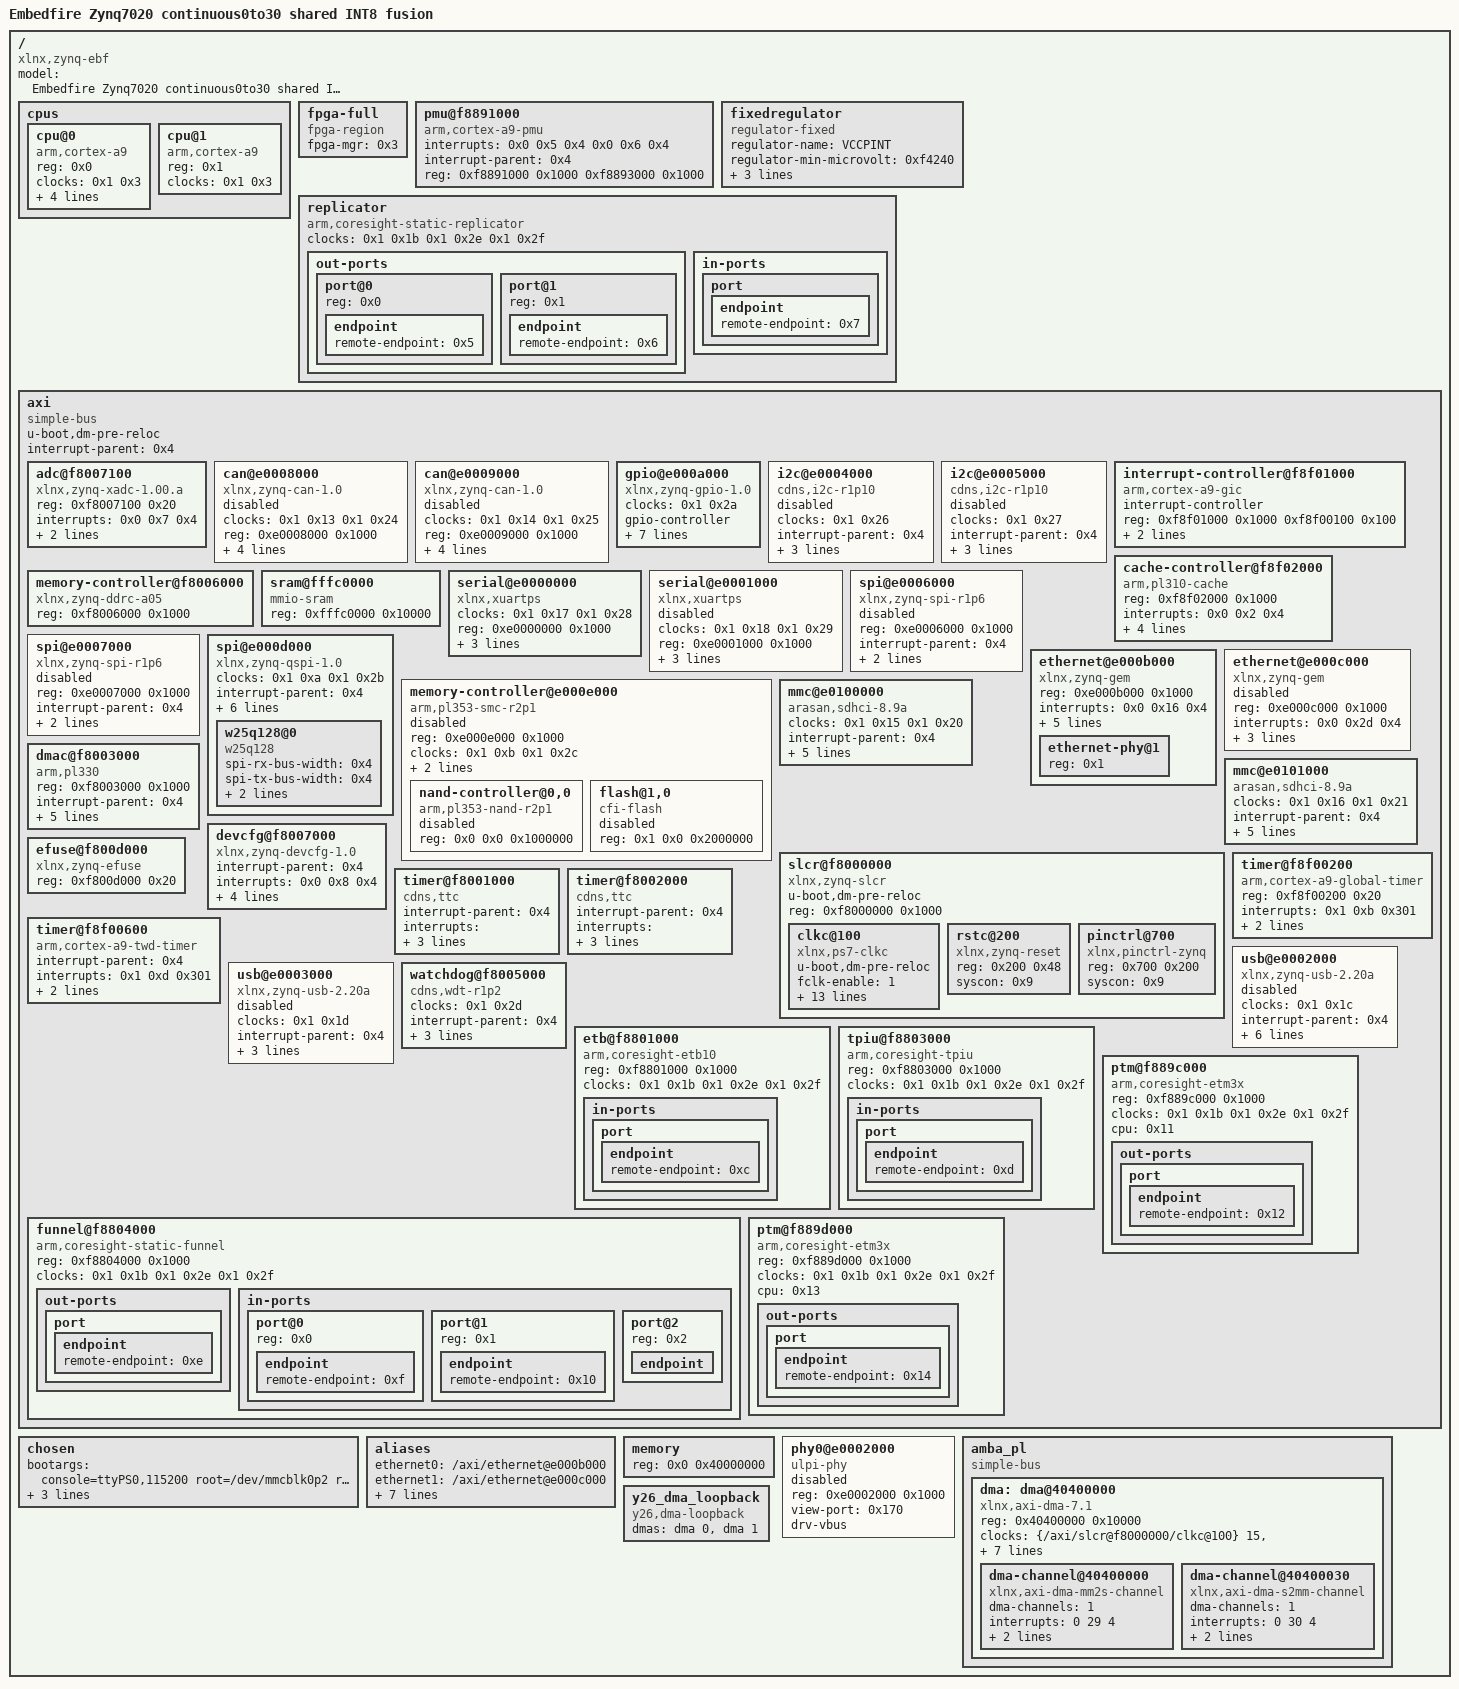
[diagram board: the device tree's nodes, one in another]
/*
 * Minimal PL experiment using the existing board FSBL, kernel and SD rootfs.
 * factory-base.dtsi is decoded from the original /boot/dtb/zynq7020.dtb;
 * its source SHA256 and the actual BOOT.BIN evidence are in verification.json.
 * This is a COMPLETE boot DT, not an overlay to apply to a running old design.
 */
/dts-v1/;

/ {
	#address-cells = <0x1>;
	#size-cells = <0x1>;
	compatible = "xlnx,zynq-ebf", "xlnx,zynq-7000";
	model = "Embedfire ZYNQ Board";

	cpus {
		#address-cells = <0x1>;
		#size-cells = <0x0>;

		cpu@0 {
			compatible = "arm,cortex-a9";
			device_type = "cpu";
			reg = <0x0>;
			clocks = <0x1 0x3>;
			clock-latency = <0x3e8>;
			cpu0-supply = <0x2>;
			operating-points = <0xa2c2b 0xf4240 0x51616 0xf4240>;
			phandle = <0x11>;
		};

		cpu@1 {
			compatible = "arm,cortex-a9";
			device_type = "cpu";
			reg = <0x1>;
			clocks = <0x1 0x3>;
			phandle = <0x13>;
		};
	};

	fpga-full {
		compatible = "fpga-region";
		fpga-mgr = <0x3>;
		#address-cells = <0x1>;
		#size-cells = <0x1>;
		ranges;
		phandle = <0x1a>;
	};

	pmu@f8891000 {
		compatible = "arm,cortex-a9-pmu";
		interrupts = <0x0 0x5 0x4 0x0 0x6 0x4>;
		interrupt-parent = <0x4>;
		reg = <0xf8891000 0x1000 0xf8893000 0x1000>;
	};

	fixedregulator {
		compatible = "regulator-fixed";
		regulator-name = "VCCPINT";
		regulator-min-microvolt = <0xf4240>;
		regulator-max-microvolt = <0xf4240>;
		regulator-boot-on;
		regulator-always-on;
		phandle = <0x2>;
	};

	replicator {
		compatible = "arm,coresight-static-replicator";
		clocks = <0x1 0x1b 0x1 0x2e 0x1 0x2f>;
		clock-names = "apb_pclk", "dbg_trc", "dbg_apb";

		out-ports {
			#address-cells = <0x1>;
			#size-cells = <0x0>;

			port@0 {
				reg = <0x0>;

				endpoint {
					remote-endpoint = <0x5>;
					phandle = <0xd>;
				};
			};

			port@1 {
				reg = <0x1>;

				endpoint {
					remote-endpoint = <0x6>;
					phandle = <0xc>;
				};
			};
		};

		in-ports {

			port {

				endpoint {
					remote-endpoint = <0x7>;
					phandle = <0xe>;
				};
			};
		};
	};

	axi {
		u-boot,dm-pre-reloc;
		compatible = "simple-bus";
		#address-cells = <0x1>;
		#size-cells = <0x1>;
		interrupt-parent = <0x4>;
		ranges;
		phandle = <0x1b>;

		adc@f8007100 {
			compatible = "xlnx,zynq-xadc-1.00.a";
			reg = <0xf8007100 0x20>;
			interrupts = <0x0 0x7 0x4>;
			interrupt-parent = <0x4>;
			clocks = <0x1 0xc>;
			phandle = <0x1c>;
		};

		can@e0008000 {
			compatible = "xlnx,zynq-can-1.0";
			status = "okay";
			clocks = <0x1 0x13 0x1 0x24>;
			clock-names = "can_clk", "pclk";
			reg = <0xe0008000 0x1000>;
			interrupts = <0x0 0x1c 0x4>;
			interrupt-parent = <0x4>;
			tx-fifo-depth = <0x40>;
			rx-fifo-depth = <0x40>;
			phandle = <0x1d>;
		};

		can@e0009000 {
			compatible = "xlnx,zynq-can-1.0";
			status = "disabled";
			clocks = <0x1 0x14 0x1 0x25>;
			clock-names = "can_clk", "pclk";
			reg = <0xe0009000 0x1000>;
			interrupts = <0x0 0x33 0x4>;
			interrupt-parent = <0x4>;
			tx-fifo-depth = <0x40>;
			rx-fifo-depth = <0x40>;
			phandle = <0x1e>;
		};

		gpio@e000a000 {
			compatible = "xlnx,zynq-gpio-1.0";
			#gpio-cells = <0x2>;
			clocks = <0x1 0x2a>;
			gpio-controller;
			interrupt-controller;
			#interrupt-cells = <0x2>;
			interrupt-parent = <0x4>;
			interrupts = <0x0 0x14 0x4>;
			reg = <0xe000a000 0x1000>;
			emio-gpio-width = <0x10>;
			gpio-mask-high = <0x0>;
			gpio-mask-low = <0x5600>;
			phandle = <0xa>;
		};

		i2c@e0004000 {
			compatible = "cdns,i2c-r1p10";
			status = "okay";
			clocks = <0x1 0x26>;
			interrupt-parent = <0x4>;
			interrupts = <0x0 0x19 0x4>;
			reg = <0xe0004000 0x1000>;
			#address-cells = <0x1>;
			#size-cells = <0x0>;
			clock-frequency = <0x61a80>;
			phandle = <0x1f>;
		};

		i2c@e0005000 {
			compatible = "cdns,i2c-r1p10";
			status = "okay";
			clocks = <0x1 0x27>;
			interrupt-parent = <0x4>;
			interrupts = <0x0 0x30 0x4>;
			reg = <0xe0005000 0x1000>;
			#address-cells = <0x1>;
			#size-cells = <0x0>;
			clock-frequency = <0x61a80>;
			phandle = <0x20>;
		};

		interrupt-controller@f8f01000 {
			compatible = "arm,cortex-a9-gic";
			#interrupt-cells = <0x3>;
			interrupt-controller;
			reg = <0xf8f01000 0x1000 0xf8f00100 0x100>;
			num_cpus = <0x2>;
			num_interrupts = <0x60>;
			phandle = <0x4>;
		};

		cache-controller@f8f02000 {
			compatible = "arm,pl310-cache";
			reg = <0xf8f02000 0x1000>;
			interrupts = <0x0 0x2 0x4>;
			arm,data-latency = <0x3 0x2 0x2>;
			arm,tag-latency = <0x2 0x2 0x2>;
			cache-unified;
			cache-level = <0x2>;
			phandle = <0x21>;
		};

		memory-controller@f8006000 {
			compatible = "xlnx,zynq-ddrc-a05";
			reg = <0xf8006000 0x1000>;
			phandle = <0x22>;
		};

		sram@fffc0000 {
			compatible = "mmio-sram";
			reg = <0xfffc0000 0x10000>;
			phandle = <0x23>;
		};

		serial@e0000000 {
			compatible = "xlnx,xuartps", "cdns,uart-r1p8";
			status = "okay";
			clocks = <0x1 0x17 0x1 0x28>;
			clock-names = "uart_clk", "pclk";
			reg = <0xe0000000 0x1000>;
			interrupts = <0x0 0x1b 0x4>;
			cts-override;
			device_type = "serial";
			port-number = <0x0>;
			phandle = <0x24>;
		};

		serial@e0001000 {
			compatible = "xlnx,xuartps", "cdns,uart-r1p8";
			status = "okay";
			clocks = <0x1 0x18 0x1 0x29>;
			clock-names = "uart_clk", "pclk";
			reg = <0xe0001000 0x1000>;
			interrupts = <0x0 0x32 0x4>;
			cts-override;
			device_type = "serial";
			port-number = <0x2>;
			phandle = <0x25>;
		};

		spi@e0006000 {
			compatible = "xlnx,zynq-spi-r1p6";
			reg = <0xe0006000 0x1000>;
			status = "disabled";
			interrupt-parent = <0x4>;
			interrupts = <0x0 0x1a 0x4>;
			clocks = <0x1 0x19 0x1 0x22>;
			clock-names = "ref_clk", "pclk";
			#address-cells = <0x1>;
			#size-cells = <0x0>;
			phandle = <0x26>;
		};

		spi@e0007000 {
			compatible = "xlnx,zynq-spi-r1p6";
			reg = <0xe0007000 0x1000>;
			status = "disabled";
			interrupt-parent = <0x4>;
			interrupts = <0x0 0x31 0x4>;
			clocks = <0x1 0x1a 0x1 0x23>;
			clock-names = "ref_clk", "pclk";
			#address-cells = <0x1>;
			#size-cells = <0x0>;
			phandle = <0x27>;
		};

		spi@e000d000 {
			clock-names = "ref_clk", "pclk";
			clocks = <0x1 0xa 0x1 0x2b>;
			compatible = "xlnx,zynq-qspi-1.0";
			status = "okay";
			interrupt-parent = <0x4>;
			interrupts = <0x0 0x13 0x4>;
			reg = <0xe000d000 0x1000>;
			#address-cells = <0x1>;
			#size-cells = <0x0>;
			is-dual = <0x0>;
			num-cs = <0x1>;
			spi-rx-bus-width = <0x4>;
			spi-tx-bus-width = <0x4>;
			phandle = <0x28>;

			w25q128@0 {
				#address-cells = <0x1>;
				#size-cells = <0x1>;
				spi-rx-bus-width = <0x4>;
				spi-tx-bus-width = <0x4>;
				compatible = "w25q128", "jedec,spi-nor";
				reg = <0x0>;
				spi-max-frequency = <0x2faf080>;
				phandle = <0x29>;
			};
		};

		ethernet@e000b000 {
			compatible = "xlnx,zynq-gem", "cdns,zynq-gem", "cdns,gem";
			reg = <0xe000b000 0x1000>;
			status = "okay";
			interrupts = <0x0 0x16 0x4>;
			clocks = <0x1 0x1e 0x1 0x1e 0x1 0xd>;
			clock-names = "pclk", "hclk", "tx_clk";
			#address-cells = <0x1>;
			#size-cells = <0x0>;
			phy-mode = "rgmii-id";
			xlnx,ptp-enet-clock = <0x69f6bcb>;
			local-mac-address = [00 0a 35 20 8b 89];
			phy-handle = <0x8>;
			phandle = <0x2a>;

			ethernet-phy@1 {
				reg = <0x1>;
				device_type = "ethernet-phy";
				phandle = <0x8>;
			};
		};

		ethernet@e000c000 {
			compatible = "xlnx,zynq-gem", "cdns,zynq-gem", "cdns,gem";
			reg = <0xe000c000 0x1000>;
			status = "okay";
			interrupts = <0x0 0x2d 0x4>;
			clocks = <0x1 0x1f 0x1 0x1f 0x1 0xe>;
			clock-names = "pclk", "hclk", "tx_clk";
			#address-cells = <0x1>;
			#size-cells = <0x0>;
			phy-mode = "gmii";
			xlnx,ptp-enet-clock = <0x69f6bcb>;
			phandle = <0x2b>;
		};

		memory-controller@e000e000 {
			compatible = "arm,pl353-smc-r2p1", "arm,primecell";
			reg = <0xe000e000 0x1000>;
			status = "disabled";
			clock-names = "memclk", "apb_pclk";
			clocks = <0x1 0xb 0x1 0x2c>;
			ranges = <0x0 0x0 0xe1000000 0x1000000 0x1 0x0 0xe2000000 0x2000000 0x2 0x0 0xe4000000 0x2000000>;
			#address-cells = <0x2>;
			#size-cells = <0x1>;
			interrupt-parent = <0x4>;
			interrupts = <0x0 0x12 0x4>;
			phandle = <0x2c>;

			nand-controller@0,0 {
				compatible = "arm,pl353-nand-r2p1";
				reg = <0x0 0x0 0x1000000>;
				status = "disabled";
				#address-cells = <0x1>;
				#size-cells = <0x0>;
				phandle = <0x2d>;
			};

			flash@1,0 {
				status = "disabled";
				compatible = "cfi-flash";
				reg = <0x1 0x0 0x2000000>;
				#address-cells = <0x1>;
				#size-cells = <0x1>;
				phandle = <0x2e>;
			};
		};

		mmc@e0100000 {
			compatible = "arasan,sdhci-8.9a";
			status = "okay";
			clock-names = "clk_xin", "clk_ahb";
			clocks = <0x1 0x15 0x1 0x20>;
			interrupt-parent = <0x4>;
			interrupts = <0x0 0x18 0x4>;
			reg = <0xe0100000 0x1000>;
			xlnx,has-cd = <0x1>;
			xlnx,has-power = <0x0>;
			xlnx,has-wp = <0x0>;
			phandle = <0x2f>;
		};

		mmc@e0101000 {
			compatible = "arasan,sdhci-8.9a";
			status = "okay";
			clock-names = "clk_xin", "clk_ahb";
			clocks = <0x1 0x16 0x1 0x21>;
			interrupt-parent = <0x4>;
			interrupts = <0x0 0x2f 0x4>;
			reg = <0xe0101000 0x1000>;
			xlnx,has-cd = <0x0>;
			xlnx,has-power = <0x0>;
			xlnx,has-wp = <0x0>;
			phandle = <0x30>;
		};

		slcr@f8000000 {
			u-boot,dm-pre-reloc;
			#address-cells = <0x1>;
			#size-cells = <0x1>;
			compatible = "xlnx,zynq-slcr", "syscon", "simple-mfd";
			reg = <0xf8000000 0x1000>;
			ranges;
			phandle = <0x9>;

			clkc@100 {
				u-boot,dm-pre-reloc;
				#clock-cells = <0x1>;
				compatible = "xlnx,ps7-clkc";
				fclk-enable = <0x7>;
				clock-output-names = "armpll", "ddrpll", "iopll", "cpu_6or4x", "cpu_3or2x", "cpu_2x", "cpu_1x", "ddr2x", "ddr3x", "dci", "lqspi", "smc", "pcap", "gem0", "gem1", "fclk0", "fclk1", "fclk2", "fclk3", "can0", "can1", "sdio0", "sdio1", "uart0", "uart1", "spi0", "spi1", "dma", "usb0_aper", "usb1_aper", "gem0_aper", "gem1_aper", "sdio0_aper", "sdio1_aper", "spi0_aper", "spi1_aper", "can0_aper", "can1_aper", "i2c0_aper", "i2c1_aper", "uart0_aper", "uart1_aper", "gpio_aper", "lqspi_aper", "smc_aper", "swdt", "dbg_trc", "dbg_apb";
				reg = <0x100 0x100>;
				ps-clk-frequency = <0x1fca055>;
				phandle = <0x1>;
			};

			rstc@200 {
				compatible = "xlnx,zynq-reset";
				reg = <0x200 0x48>;
				#reset-cells = <0x1>;
				syscon = <0x9>;
				phandle = <0x31>;
			};

			pinctrl@700 {
				compatible = "xlnx,pinctrl-zynq";
				reg = <0x700 0x200>;
				syscon = <0x9>;
				phandle = <0x32>;
			};
		};

		dmac@f8003000 {
			compatible = "arm,pl330", "arm,primecell";
			reg = <0xf8003000 0x1000>;
			interrupt-parent = <0x4>;
			interrupt-names = "abort", "dma0", "dma1", "dma2", "dma3", "dma4", "dma5", "dma6", "dma7";
			interrupts = <0x0 0xd 0x4 0x0 0xe 0x4 0x0 0xf 0x4 0x0 0x10 0x4 0x0 0x11 0x4 0x0 0x28 0x4 0x0 0x29 0x4 0x0 0x2a 0x4 0x0 0x2b 0x4>;
			#dma-cells = <0x1>;
			#dma-channels = <0x8>;
			#dma-requests = <0x4>;
			clocks = <0x1 0x1b>;
			clock-names = "apb_pclk";
			phandle = <0x33>;
		};

		devcfg@f8007000 {
			compatible = "xlnx,zynq-devcfg-1.0";
			interrupt-parent = <0x4>;
			interrupts = <0x0 0x8 0x4>;
			reg = <0xf8007000 0x100>;
			clocks = <0x1 0xc 0x1 0xf 0x1 0x10 0x1 0x11 0x1 0x12>;
			clock-names = "ref_clk", "fclk0", "fclk1", "fclk2", "fclk3";
			syscon = <0x9>;
			phandle = <0x3>;
		};

		efuse@f800d000 {
			compatible = "xlnx,zynq-efuse";
			reg = <0xf800d000 0x20>;
			phandle = <0x34>;
		};

		timer@f8f00200 {
			compatible = "arm,cortex-a9-global-timer";
			reg = <0xf8f00200 0x20>;
			interrupts = <0x1 0xb 0x301>;
			interrupt-parent = <0x4>;
			clocks = <0x1 0x4>;
			phandle = <0x35>;
		};

		timer@f8001000 {
			interrupt-parent = <0x4>;
			interrupts = <0x0 0xa 0x4 0x0 0xb 0x4 0x0 0xc 0x4>;
			compatible = "cdns,ttc";
			clocks = <0x1 0x6>;
			reg = <0xf8001000 0x1000>;
			phandle = <0x36>;
		};

		timer@f8002000 {
			interrupt-parent = <0x4>;
			interrupts = <0x0 0x25 0x4 0x0 0x26 0x4 0x0 0x27 0x4>;
			compatible = "cdns,ttc";
			clocks = <0x1 0x6>;
			reg = <0xf8002000 0x1000>;
			phandle = <0x37>;
		};

		timer@f8f00600 {
			interrupt-parent = <0x4>;
			interrupts = <0x1 0xd 0x301>;
			compatible = "arm,cortex-a9-twd-timer";
			reg = <0xf8f00600 0x20>;
			clocks = <0x1 0x4>;
			phandle = <0x38>;
		};

		usb@e0002000 {
			compatible = "xlnx,zynq-usb-2.20a", "chipidea,usb2";
			status = "okay";
			clocks = <0x1 0x1c>;
			interrupt-parent = <0x4>;
			interrupts = <0x0 0x15 0x4>;
			reg = <0xe0002000 0x1000>;
			phy_type = "ulpi";
			usb-reset = <0xa 0xd 0x0>;
			dr_mode = "otg";
			usb-phy = <0xb>;
			phandle = <0x39>;
		};

		usb@e0003000 {
			compatible = "xlnx,zynq-usb-2.20a", "chipidea,usb2";
			status = "disabled";
			clocks = <0x1 0x1d>;
			interrupt-parent = <0x4>;
			interrupts = <0x0 0x2c 0x4>;
			reg = <0xe0003000 0x1000>;
			phy_type = "ulpi";
			phandle = <0x3a>;
		};

		watchdog@f8005000 {
			clocks = <0x1 0x2d>;
			compatible = "cdns,wdt-r1p2";
			interrupt-parent = <0x4>;
			interrupts = <0x0 0x9 0x1>;
			reg = <0xf8005000 0x1000>;
			timeout-sec = <0xa>;
			phandle = <0x3b>;
		};

		etb@f8801000 {
			compatible = "arm,coresight-etb10", "arm,primecell";
			reg = <0xf8801000 0x1000>;
			clocks = <0x1 0x1b 0x1 0x2e 0x1 0x2f>;
			clock-names = "apb_pclk", "dbg_trc", "dbg_apb";

			in-ports {

				port {

					endpoint {
						remote-endpoint = <0xc>;
						phandle = <0x6>;
					};
				};
			};
		};

		tpiu@f8803000 {
			compatible = "arm,coresight-tpiu", "arm,primecell";
			reg = <0xf8803000 0x1000>;
			clocks = <0x1 0x1b 0x1 0x2e 0x1 0x2f>;
			clock-names = "apb_pclk", "dbg_trc", "dbg_apb";

			in-ports {

				port {

					endpoint {
						remote-endpoint = <0xd>;
						phandle = <0x5>;
					};
				};
			};
		};

		funnel@f8804000 {
			compatible = "arm,coresight-static-funnel", "arm,primecell";
			reg = <0xf8804000 0x1000>;
			clocks = <0x1 0x1b 0x1 0x2e 0x1 0x2f>;
			clock-names = "apb_pclk", "dbg_trc", "dbg_apb";

			out-ports {

				port {

					endpoint {
						remote-endpoint = <0xe>;
						phandle = <0x7>;
					};
				};
			};

			in-ports {
				#address-cells = <0x1>;
				#size-cells = <0x0>;

				port@0 {
					reg = <0x0>;

					endpoint {
						remote-endpoint = <0xf>;
						phandle = <0x12>;
					};
				};

				port@1 {
					reg = <0x1>;

					endpoint {
						remote-endpoint = <0x10>;
						phandle = <0x14>;
					};
				};

				port@2 {
					reg = <0x2>;

					endpoint {
						phandle = <0x3c>;
					};
				};
			};
		};

		ptm@f889c000 {
			compatible = "arm,coresight-etm3x", "arm,primecell";
			reg = <0xf889c000 0x1000>;
			clocks = <0x1 0x1b 0x1 0x2e 0x1 0x2f>;
			clock-names = "apb_pclk", "dbg_trc", "dbg_apb";
			cpu = <0x11>;

			out-ports {

				port {

					endpoint {
						remote-endpoint = <0x12>;
						phandle = <0xf>;
					};
				};
			};
		};

		ptm@f889d000 {
			compatible = "arm,coresight-etm3x", "arm,primecell";
			reg = <0xf889d000 0x1000>;
			clocks = <0x1 0x1b 0x1 0x2e 0x1 0x2f>;
			clock-names = "apb_pclk", "dbg_trc", "dbg_apb";
			cpu = <0x13>;

			out-ports {

				port {

					endpoint {
						remote-endpoint = <0x14>;
						phandle = <0x10>;
					};
				};
			};
		};
	};

	amba_pl {
		#address-cells = <0x1>;
		#size-cells = <0x1>;
		compatible = "simple-bus";
		ranges;
		phandle = <0x3d>;

		audio_formatter@43c40000 {
			clock-names = "s_axi_lite_aclk", "m_axis_mm2s_aclk", "aud_mclk", "s_axis_s2mm_aclk";
			clocks = <0x1 0xf 0x1 0xf 0x15 0x1 0xf>;
			compatible = "xlnx,audio-formatter-1.0", "xlnx,audio-formatter-1.0";
			interrupt-names = "irq_mm2s", "irq_s2mm";
			interrupt-parent = <0x4>;
			interrupts = <0x0 0x21 0x4 0x0 0x22 0x4>;
			reg = <0x43c40000 0x10000>;
			xlnx,include-mm2s = <0x1>;
			xlnx,include-s2mm = <0x1>;
			xlnx,max-num-channels-mm2s = <0x2>;
			xlnx,max-num-channels-s2mm = <0x2>;
			xlnx,mm2s-addr-width = <0x40>;
			xlnx,mm2s-async-clock = <0x1>;
			xlnx,mm2s-dataformat = <0x3>;
			xlnx,packing-mode-mm2s = <0x0>;
			xlnx,packing-mode-s2mm = <0x0>;
			xlnx,rx = <0x16>;
			xlnx,s2mm-addr-width = <0x40>;
			xlnx,s2mm-async-clock = <0x1>;
			xlnx,s2mm-dataformat = <0x1>;
			xlnx,tx = <0x17>;
			phandle = <0x18>;
		};

		misc_clk_0 {
			#clock-cells = <0x0>;
			clock-frequency = <0x5f5e100>;
			compatible = "fixed-clock";
			phandle = <0x15>;
		};

		axi_dynclk@43c20000 {
			clock-names = "REF_CLK_I", "s_axi_lite_aclk";
			clocks = <0x1 0xf 0x1 0xf>;
			compatible = "xlnx,axi-dynclk-1.2";
			reg = <0x43c20000 0x10000>;
			phandle = <0x3e>;
		};

		i2s_receiver@43c50000 {
			aud_mclk = <0x5f5e100>;
			clock-names = "s_axi_ctrl_aclk", "aud_mclk", "m_axis_aud_aclk";
			clocks = <0x1 0xf 0x15 0x1 0xf>;
			compatible = "xlnx,i2s-receiver-1.0", "xlnx,i2s-receiver-1.0";
			interrupt-names = "irq";
			interrupt-parent = <0x4>;
			interrupts = <0x0 0x23 0x4>;
			reg = <0x43c50000 0x10000>;
			xlnx,depth = <0x80>;
			xlnx,dwidth = <0x18>;
			xlnx,num-channels = <0x1>;
			xlnx,snd-pcm = <0x18>;
			phandle = <0x16>;
		};

		i2s_transmitter@43c60000 {
			aud_mclk = <0x5f5e100>;
			clock-names = "s_axi_ctrl_aclk", "aud_mclk", "s_axis_aud_aclk";
			clocks = <0x1 0xf 0x15 0x1 0xf>;
			compatible = "xlnx,i2s-transmitter-1.0", "xlnx,i2s-transmitter-1.0";
			interrupt-names = "irq";
			interrupt-parent = <0x4>;
			interrupts = <0x0 0x20 0x4>;
			reg = <0x43c60000 0x10000>;
			xlnx,depth = <0x80>;
			xlnx,dwidth = <0x18>;
			xlnx,num-channels = <0x1>;
			xlnx,snd-pcm = <0x18>;
			phandle = <0x17>;
		};

		i2c@41600000 {
			#address-cells = <0x1>;
			#size-cells = <0x0>;
			clock-names = "s_axi_aclk";
			clocks = <0x1 0xf>;
			compatible = "xlnx,axi-iic-2.1", "xlnx,xps-iic-2.00.a";
			interrupt-names = "iic2intc_irpt";
			interrupt-parent = <0x4>;
			interrupts = <0x0 0x1f 0x4>;
			reg = <0x41600000 0x10000>;
			phandle = <0x3f>;
		};

		serial@42c00000 {
			clock-names = "s_axi_aclk";
			clocks = <0x1 0xf>;
			compatible = "xlnx,axi-uartlite-2.0", "xlnx,xps-uartlite-1.00.a";
			current-speed = <0x1c200>;
			device_type = "serial";
			interrupt-names = "interrupt";
			interrupt-parent = <0x4>;
			interrupts = <0x0 0x1e 0x1>;
			port-number = <0x1>;
			reg = <0x42c00000 0x10000>;
			xlnx,baudrate = <0x1c200>;
			xlnx,data-bits = <0x8>;
			xlnx,odd-parity = <0x0>;
			xlnx,s-axi-aclk-freq-hz-d = "100.0";
			xlnx,use-parity = <0x0>;
			phandle = <0x40>;
		};

		ov5640_to_lcd@43c30000 {
			clock-names = "s00_axi_aclk";
			clocks = <0x1 0xf>;
			compatible = "xlnx,ov5640-to-lcd-1.0";
			reg = <0x43c30000 0x10000>;
			xlnx,s00-axi-addr-width = <0x4>;
			xlnx,s00-axi-data-width = <0x20>;
			phandle = <0x41>;
		};

		v_frmbuf_wr@43cb0000 {
			#dma-cells = <0x1>;
			clock-names = "ap_clk";
			clocks = <0x1 0x10>;
			compatible = "xlnx,v-frmbuf-wr-2.4", "xlnx,axi-frmbuf-wr-v2.2";
			interrupt-names = "interrupt";
			interrupt-parent = <0x4>;
			interrupts = <0x0 0x36 0x4>;
			reg = <0x43cb0000 0x10000>;
			reset-gpios = <0x19 0x2 0x1>;
			xlnx,dma-addr-width = <0x20>;
			xlnx,dma-align = <0x8>;
			xlnx,max-height = <0x438>;
			xlnx,max-width = <0x780>;
			xlnx,pixels-per-clock = <0x1>;
			xlnx,s-axi-ctrl-addr-width = <0x7>;
			xlnx,s-axi-ctrl-data-width = <0x20>;
			xlnx,vid-formats = "rgb888", "bgr888";
			xlnx,video-width = <0x8>;
			phandle = <0x42>;
		};

		gpio@41210000 {
			#gpio-cells = <0x2>;
			clock-names = "s_axi_aclk";
			clocks = <0x1 0xf>;
			compatible = "xlnx,axi-gpio-2.0", "xlnx,xps-gpio-1.00.a";
			gpio-controller;
			reg = <0x41210000 0x10000>;
			xlnx,all-inputs = <0x0>;
			xlnx,all-inputs-2 = <0x0>;
			xlnx,all-outputs = <0x1>;
			xlnx,all-outputs-2 = <0x0>;
			xlnx,dout-default = <0x0>;
			xlnx,dout-default-2 = <0x0>;
			xlnx,gpio-width = <0x3>;
			xlnx,gpio2-width = <0x20>;
			xlnx,interrupt-present = <0x0>;
			xlnx,is-dual = <0x0>;
			xlnx,tri-default = <0xffffffff>;
			xlnx,tri-default-2 = <0xffffffff>;
			phandle = <0x19>;
		};

		axi_dynclk@43c90000 {
			clock-names = "REF_CLK_I", "s_axi_lite_aclk";
			clocks = <0x1 0xf 0x1 0xf>;
			compatible = "xlnx,axi-dynclk-1.2";
			reg = <0x43c90000 0x10000>;
			phandle = <0x43>;
		};

		v_frmbuf_rd@43ca0000 {
			#dma-cells = <0x1>;
			clock-names = "ap_clk";
			clocks = <0x1 0x11>;
			compatible = "xlnx,v-frmbuf-rd-2.4", "xlnx,axi-frmbuf-rd-v2.2";
			interrupt-names = "interrupt";
			interrupt-parent = <0x4>;
			interrupts = <0x0 0x34 0x4>;
			reg = <0x43ca0000 0x10000>;
			reset-gpios = <0x19 0x1 0x1>;
			xlnx,dma-addr-width = <0x20>;
			xlnx,dma-align = <0x8>;
			xlnx,max-height = <0x438>;
			xlnx,max-width = <0x780>;
			xlnx,pixels-per-clock = <0x1>;
			xlnx,s-axi-ctrl-addr-width = <0x7>;
			xlnx,s-axi-ctrl-data-width = <0x20>;
			xlnx,vid-formats = "rgb888", "bgr888";
			xlnx,video-width = <0x8>;
			phandle = <0x44>;
		};

		v_tc@43c80000 {
			clock-names = "clk", "s_axi_aclk";
			clocks = <0x15 0x1 0xf>;
			compatible = "xlnx,v-tc-6.2", "xlnx,v-tc-6.1";
			interrupt-names = "irq";
			interrupt-parent = <0x4>;
			interrupts = <0x0 0x35 0x4>;
			reg = <0x43c80000 0x10000>;
			xlnx,generator;
			phandle = <0x45>;
		};

		axi_dynclk@43cc0000 {
			clock-names = "REF_CLK_I", "s_axi_lite_aclk";
			clocks = <0x1 0xf 0x1 0xf>;
			compatible = "xlnx,axi-dynclk-1.2";
			reg = <0x43cc0000 0x10000>;
			phandle = <0x46>;
		};

		tft_lcd@43c10000 {
			clock-names = "pixel_clk", "s00_axi_aclk";
			clocks = <0x15 0x1 0xf>;
			compatible = "xlnx,tft-lcd-1.0";
			reg = <0x43c10000 0x10000>;
			xlnx,s00-axi-addr-width = <0x4>;
			xlnx,s00-axi-data-width = <0x20>;
			phandle = <0x47>;
		};

		v_frmbuf_rd@43c70000 {
			#dma-cells = <0x1>;
			clock-names = "ap_clk";
			clocks = <0x1 0x11>;
			compatible = "xlnx,v-frmbuf-rd-2.4", "xlnx,axi-frmbuf-rd-v2.2";
			interrupt-names = "interrupt";
			interrupt-parent = <0x4>;
			interrupts = <0x0 0x24 0x4>;
			reg = <0x43c70000 0x10000>;
			reset-gpios = <0x19 0x0 0x1>;
			xlnx,dma-addr-width = <0x20>;
			xlnx,dma-align = <0x8>;
			xlnx,max-height = <0x438>;
			xlnx,max-width = <0x780>;
			xlnx,pixels-per-clock = <0x1>;
			xlnx,s-axi-ctrl-addr-width = <0x7>;
			xlnx,s-axi-ctrl-data-width = <0x20>;
			xlnx,vid-formats = "rgb888", "bgr888";
			xlnx,video-width = <0x8>;
			phandle = <0x48>;
		};

		v_tc@43c00000 {
			clock-names = "clk", "s_axi_aclk";
			clocks = <0x15 0x1 0xf>;
			compatible = "xlnx,v-tc-6.2", "xlnx,v-tc-6.1";
			interrupt-names = "irq";
			interrupt-parent = <0x4>;
			interrupts = <0x0 0x1d 0x4>;
			reg = <0x43c00000 0x10000>;
			xlnx,generator;
			phandle = <0x49>;
		};
	};

	chosen {
		bootargs = "console=ttyPS0,115200 earlycon";
		stdout-path = "serial0:115200n8";
	};

	aliases {
		ethernet0 = "/axi/ethernet@e000b000";
		ethernet1 = "/axi/ethernet@e000c000";
		i2c0 = "/axi/i2c@e0004000";
		i2c1 = "/axi/i2c@e0005000";
		i2c2 = "/amba_pl/i2c@41600000";
		serial0 = "/axi/serial@e0000000";
		serial1 = "/axi/serial@e0001000";
		serial2 = "/amba_pl/serial@42c00000";
		spi0 = "/axi/spi@e000d000";
		mmc0 = "/axi/mmc@e0100000";
		mmc1 = "/axi/mmc@e0101000";
	};

	memory {
		device_type = "memory";
		reg = <0x0 0x40000000>;
	};

	phy0@e0002000 {
		compatible = "ulpi-phy";
		#phy-cells = <0x0>;
		reg = <0xe0002000 0x1000>;
		view-port = <0x170>;
		drv-vbus;
		phandle = <0xb>;
	};

	__symbols__ {
		cpu0 = "/cpus/cpu@0";
		cpu1 = "/cpus/cpu@1";
		fpga_full = "/fpga-full";
		regulator_vccpint = "/fixedregulator";
		replicator_out_port0 = "/replicator/out-ports/port@0/endpoint";
		replicator_out_port1 = "/replicator/out-ports/port@1/endpoint";
		replicator_in_port0 = "/replicator/in-ports/port/endpoint";
		amba = "/axi";
		adc = "/axi/adc@f8007100";
		can0 = "/axi/can@e0008000";
		can1 = "/axi/can@e0009000";
		gpio0 = "/axi/gpio@e000a000";
		i2c0 = "/axi/i2c@e0004000";
		i2c1 = "/axi/i2c@e0005000";
		intc = "/axi/interrupt-controller@f8f01000";
		L2 = "/axi/cache-controller@f8f02000";
		mc = "/axi/memory-controller@f8006000";
		ocm = "/axi/sram@fffc0000";
		uart0 = "/axi/serial@e0000000";
		uart1 = "/axi/serial@e0001000";
		spi0 = "/axi/spi@e0006000";
		spi1 = "/axi/spi@e0007000";
		qspi = "/axi/spi@e000d000";
		w25q128 = "/axi/spi@e000d000/w25q128@0";
		gem0 = "/axi/ethernet@e000b000";
		phy0 = "/axi/ethernet@e000b000/ethernet-phy@1";
		gem1 = "/axi/ethernet@e000c000";
		smcc = "/axi/memory-controller@e000e000";
		nfc0 = "/axi/memory-controller@e000e000/nand-controller@0,0";
		nor0 = "/axi/memory-controller@e000e000/flash@1,0";
		sdhci0 = "/axi/mmc@e0100000";
		sdhci1 = "/axi/mmc@e0101000";
		slcr = "/axi/slcr@f8000000";
		clkc = "/axi/slcr@f8000000/clkc@100";
		rstc = "/axi/slcr@f8000000/rstc@200";
		pinctrl0 = "/axi/slcr@f8000000/pinctrl@700";
		dmac_s = "/axi/dmac@f8003000";
		devcfg = "/axi/devcfg@f8007000";
		efuse = "/axi/efuse@f800d000";
		global_timer = "/axi/timer@f8f00200";
		ttc0 = "/axi/timer@f8001000";
		ttc1 = "/axi/timer@f8002000";
		scutimer = "/axi/timer@f8f00600";
		usb0 = "/axi/usb@e0002000";
		usb1 = "/axi/usb@e0003000";
		watchdog0 = "/axi/watchdog@f8005000";
		etb_in_port = "/axi/etb@f8801000/in-ports/port/endpoint";
		tpiu_in_port = "/axi/tpiu@f8803000/in-ports/port/endpoint";
		funnel_out_port = "/axi/funnel@f8804000/out-ports/port/endpoint";
		funnel0_in_port0 = "/axi/funnel@f8804000/in-ports/port@0/endpoint";
		funnel0_in_port1 = "/axi/funnel@f8804000/in-ports/port@1/endpoint";
		funnel0_in_port2 = "/axi/funnel@f8804000/in-ports/port@2/endpoint";
		ptm0_out_port = "/axi/ptm@f889c000/out-ports/port/endpoint";
		ptm1_out_port = "/axi/ptm@f889d000/out-ports/port/endpoint";
		amba_pl = "/amba_pl";
		audio_audio_formatter_0 = "/amba_pl/audio_formatter@43c40000";
		misc_clk_0 = "/amba_pl/misc_clk_0";
		audio_axi_dynclk_0 = "/amba_pl/axi_dynclk@43c20000";
		audio_i2s_receiver_0 = "/amba_pl/i2s_receiver@43c50000";
		audio_i2s_transmitter_0 = "/amba_pl/i2s_transmitter@43c60000";
		axi_iic_0 = "/amba_pl/i2c@41600000";
		axi_uartlite_0 = "/amba_pl/serial@42c00000";
		camera_ov5640_to_lcd_0 = "/amba_pl/ov5640_to_lcd@43c30000";
		camera_v_frmbuf_wr_0 = "/amba_pl/v_frmbuf_wr@43cb0000";
		frmbuf_rst_gpio = "/amba_pl/gpio@41210000";
		hdmi_display_axi_dynclk_0 = "/amba_pl/axi_dynclk@43c90000";
		hdmi_display_v_frmbuf_rd_1 = "/amba_pl/v_frmbuf_rd@43ca0000";
		hdmi_display_v_tc_1 = "/amba_pl/v_tc@43c80000";
		lcd_display_axi_dynclk_0 = "/amba_pl/axi_dynclk@43cc0000";
		lcd_display_tft_lcd_0 = "/amba_pl/tft_lcd@43c10000";
		lcd_display_v_frmbuf_rd_0 = "/amba_pl/v_frmbuf_rd@43c70000";
		lcd_display_v_tc_0 = "/amba_pl/v_tc@43c00000";
		usb_phy0 = "/phy0@e0002000";
	};
};


/ {
    model = "Embedfire Zynq7020 continuous0to30 shared INT8 fusion";

    chosen {
        bootargs = "console=ttyPS0,115200 root=/dev/mmcblk0p2 rw rootfstype=ext4 rootwait mtdparts=spi0.0:6M(boot),-(space) board=zynq7020";
        stdout-path = "/axi/serial@e0000000:115200n8";
        y26,bitstream-sha256 = "d4c8b7f9426ecddc3c4d344bd0920a61a1acc7d9a99d48fbf275665d2f463a2e";
    };

    aliases {
        /delete-property/ i2c2;
        /delete-property/ serial2;
    };

    /delete-node/ amba_pl;
    /delete-node/ __symbols__;

    amba_pl {
        #address-cells = <1>;
        #size-cells = <1>;
        compatible = "simple-bus";
        ranges;

        dma: dma@40400000 {
            compatible = "xlnx,axi-dma-7.1", "xlnx,axi-dma-1.00.a";
            reg = <0x40400000 0x10000>;
            #dma-cells = <1>;
            clock-names = "s_axi_lite_aclk", "m_axi_mm2s_aclk", "m_axi_s2mm_aclk";
            clocks = <&{/axi/slcr@f8000000/clkc@100} 15>,
                     <&{/axi/slcr@f8000000/clkc@100} 15>,
                     <&{/axi/slcr@f8000000/clkc@100} 15>;
            interrupt-parent = <&{/axi/interrupt-controller@f8f01000}>;
            interrupts = <0 29 4>, <0 30 4>;
            interrupt-names = "mm2s_introut", "s2mm_introut";
            xlnx,addrwidth = <32>;
            xlnx,sg-length-width = <23>;

            dma-channel@40400000 {
                compatible = "xlnx,axi-dma-mm2s-channel";
                dma-channels = <1>;
                interrupts = <0 29 4>;
                xlnx,datawidth = <32>;
                xlnx,device-id = <0>;
            };

            dma-channel@40400030 {
                compatible = "xlnx,axi-dma-s2mm-channel";
                dma-channels = <1>;
                interrupts = <0 30 4>;
                xlnx,datawidth = <32>;
                xlnx,device-id = <0>;
            };
        };
    };

    y26_dma_loopback {
        compatible = "y26,dma-loopback";
        dmas = <&dma 0>, <&dma 1>;
        dma-names = "tx", "rx";
    };
};

/* These factory devices require EMIO/PL circuitry absent from this bit. */
&{/axi/i2c@e0004000} { status = "disabled"; };
&{/axi/i2c@e0005000} { status = "disabled"; };
&{/axi/can@e0008000} { status = "disabled"; };
&{/axi/serial@e0001000} { status = "disabled"; };
&{/axi/ethernet@e000c000} { status = "disabled"; };

/* This experiment uses serial + GEM0; do not export the SD via USB gadget. */
&{/axi/usb@e0002000} { status = "disabled"; };
&{/phy0@e0002000} { status = "disabled"; };

&{/axi/slcr@f8000000/clkc@100} { fclk-enable = <1>; };
&{/axi/ethernet@e000b000} { local-mac-address = [d2 8d 41 73 78 64]; };
